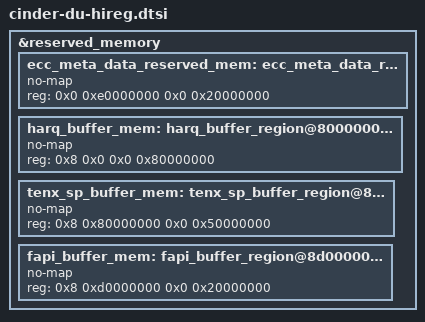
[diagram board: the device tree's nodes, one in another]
&reserved_memory {
	#address-cells = <2>;
	#size-cells = <2>;
	ranges;

	ecc_meta_data_reserved_mem: ecc_meta_data_reserved_region@e0000000 {
		no-map;
		reg = <0x0 0xe0000000 0x0 0x20000000>;
	};

	harq_buffer_mem: harq_buffer_region@800000000 {
		no-map;
		reg = <0x8 0x0 0x0 0x80000000>;
	};

	tenx_sp_buffer_mem: tenx_sp_buffer_region@880000000 {
		no-map;
		reg = <0x8 0x80000000 0x0 0x50000000>;
	};

	fapi_buffer_mem: fapi_buffer_region@8d0000000 {
		no-map;
		reg = <0x8 0xd0000000 0x0 0x20000000>;
	};

};
